# MKE02Z4 register map
Vendor: NXP Semiconductors; Series: Kinetis_E; File version: 1.6
MKE02Z4 NXP Microcontroller
CPU: CM0PLUS r0p0, little endian, no MPU, no FPU, VTOR, 2 interrupt priority bits
Registers are 32-bit, read-write, reset 0x0 unless marked. A register's access mark holds for its fields unless they carry their own. Offsets are from the block's base; lines under a group give offsets from that group; [hi:lo] are bit positions; {n}, {i} and the like mark numbered series; 'fields as' and 'values as' point back to an identical list; <NAME> marks a mode.

## Memory map
0x40020000 FTMRH size 0xD — Flash Memory
0x40031000 IRQ size 0x1 — Interrupt
0x40032000 CRC size 0xC — Cyclic Redundancy Check
0x40037000 PIT size 0x120 — Periodic Interrupt Timer
0x40038000 FTM0 size 0x9C — FlexTimer Module
0x40039000 FTM1 size 0x9C — FlexTimer Module
0x4003A000 FTM2 size 0x9C — FlexTimer Module
0x4003B000 ADC size 0x1C — Analog-to-digital converter
0x4003D000 RTC size 0xC — Real-time counter
0x40048000 SIM size 0x1C — System Integration Module
0x40049000 PORT size 0x10 — Port control and interrupts
0x40052000 WDOG size 0x8 — Watchdog timer
0x40064000 ICS size 0x5 — Clock management
0x40065000 OSC size 0x1 — Oscillator
0x40066000 I2C0 size 0xC — Inter-Integrated Circuit
0x4006A000 UART0 size 0x8 — Universal Asynchronous Receiver/Transmitter (UART)
0x4006B000 UART1 size 0x8 — Universal Asynchronous Receiver/Transmitter (UART)
0x4006C000 UART2 size 0x8 — Universal Asynchronous Receiver/Transmitter (UART)
0x40073000 ACMP0 size 0x4 — Analog comparator
0x40074000 ACMP1 size 0x4 — Analog comparator
0x40076000 SPI0 size 0x8 — Serial Peripheral Interface
0x40077000 SPI1 size 0x8 — Serial Peripheral Interface
0x40079000 KBI0 size 0x3 — Keyboard interrupts
0x4007A000 KBI1 size 0x3 — Keyboard interrupts
0x4007D000 PMC size 0x2 — Power management
0x400FF000 GPIOA size 0x1C — General Purpose Input/Output
0x400FF040 GPIOB size 0x1C — General Purpose Input/Output
0xF0002000 ROM size 0x1000 — System ROM
0xF0003000 MCM blocks up to offset 0x10 — Core Platform Miscellaneous Control Module
0xF8000000 FGPIOA size 0x1C — General Purpose Input/Output
0xF8000040 FGPIOB size 0x1C — General Purpose Input/Output

## Interrupts
5 FTMRH
6 PMC
7 IRQ (GPIOA)
8 I2C0
10 SPI0
11 SPI1
12 UART0
13 UART1
14 UART2
15 ADC
16 ACMP0
17 FTM0
18 FTM1
19 FTM2
20 RTC
21 ACMP1
22 PIT_CH0 (PIT)
23 PIT_CH1 (PIT)
24 KBI0
25 KBI1
27 ICS
28 WDOG

## IRQ — Interrupt
Base 0x40031000; register names take the prefix IRQ_
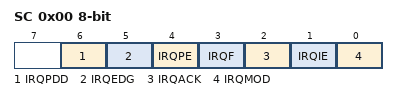
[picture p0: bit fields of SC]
0x00 SC 8-bit — Interrupt Pin Request Status and Control Register
  [6] IRQPDD — Interrupt Request (IRQ) Pull Device Disable
    0=IRQ pull device enabled if IRQPE = 1; 1=IRQ pull device disabled if IRQPE = 1
  [5] IRQEDG — Interrupt Request (IRQ) Edge Select
    0=IRQ is falling-edge or falling-edge/low-level sensitive; 1=IRQ is rising-edge or rising-edge/high-level sensitive
  [4] IRQPE — IRQ Pin Enable
    0=IRQ pin function is disabled; 1=IRQ pin function is enabled
  [3] IRQF ro — IRQ Flag
    0=No IRQ request; 1=IRQ event is detected
  [2] IRQACK wo — IRQ Acknowledge
  [1] IRQIE — IRQ Interrupt Enable
    0=Interrupt request when IRQF set is disabled (use polling); 1=Interrupt requested whenever IRQF = 1
  [0] IRQMOD — IRQ Detection Mode
    0=IRQ event is detected only on falling/rising edges; 1=IRQ event is detected on falling/rising edges and low/high levels

## CRC — Cyclic Redundancy Check
Base 0x40032000; register names take the prefix CRC_
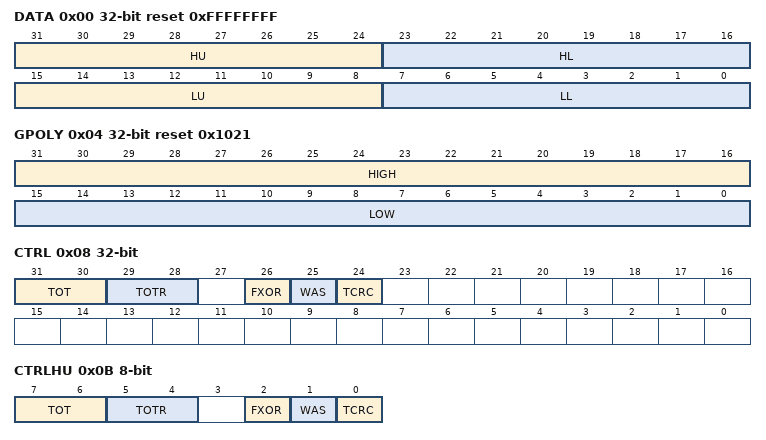
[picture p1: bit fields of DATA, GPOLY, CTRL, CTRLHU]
0x00 DATA reset 0xFFFFFFFF (CRC view) — CRC Data register
  [31:24] HU — CRC High Upper Byte
  [23:16] HL — CRC High Lower Byte
  [15:8] LU — CRC Low Upper Byte
  [7:0] LL — CRC Low Lower Byte
0x00 DATAL 16-bit reset 0xFFFF (CRC view) — CRC_DATAL register.
  [15:0] DATAL — DATAL stores the lower 16 bits of the 16/32 bit CRC
0x00 DATALL 8-bit reset 0xFF (CRC view) — CRC_DATALL register.
  [7:0] DATALL — CRCLL stores the first 8 bits of the 32 bit DATA
0x01 DATALU 8-bit reset 0xFF — CRC_DATALU register.
  [7:0] DATALU — DATALL stores the second 8 bits of the 32 bit CRC
0x02 DATAH 16-bit reset 0xFFFF (CRC view) — CRC_DATAH register.
  [15:0] DATAH — DATAH stores the high 16 bits of the 16/32 bit CRC
0x02 DATAHL 8-bit reset 0xFF (CRC view) — CRC_DATAHL register.
  [7:0] DATAHL — DATAHL stores the third 8 bits of the 32 bit CRC
0x03 DATAHU 8-bit reset 0xFF — CRC_DATAHU register.
  [7:0] DATAHU — DATAHU stores the fourth 8 bits of the 32 bit CRC
0x04 GPOLY reset 0x1021 (CRC view) — CRC Polynomial register
  [31:16] HIGH — High Polynominal Half-word
  [15:0] LOW — Low Polynominal Half-word
0x04 GPOLYL 16-bit reset 0xFFFF (CRC view) — CRC_GPOLYL register.
  [15:0] GPOLYL — POLYL stores the lower 16 bits of the 16/32 bit CRC polynomial value
0x04 GPOLYLL 8-bit reset 0xFF (CRC view) — CRC_GPOLYLL register.
  [7:0] GPOLYLL — POLYLL stores the first 8 bits of the 32 bit CRC
0x05 GPOLYLU 8-bit reset 0xFF — CRC_GPOLYLU register.
  [7:0] GPOLYLU — POLYLL stores the second 8 bits of the 32 bit CRC
0x06 GPOLYH 16-bit reset 0xFFFF (CRC view) — CRC_GPOLYH register.
  [15:0] GPOLYH — POLYH stores the high 16 bits of the 16/32 bit CRC polynomial value
0x06 GPOLYHL 8-bit reset 0xFF (CRC view) — CRC_GPOLYHL register.
  [7:0] GPOLYHL — POLYHL stores the third 8 bits of the 32 bit CRC
0x07 GPOLYHU 8-bit reset 0xFF — CRC_GPOLYHU register.
  [7:0] GPOLYHU — POLYHU stores the fourth 8 bits of the 32 bit CRC
0x08 CTRL — CRC Control register
  [31:30] TOT — Type Of Transpose For Writes
    0=No transposition; 1=Bits in bytes are transposed; bytes are not transposed; 2=Both bits in bytes and bytes are transposed; 3=Only bytes are transposed; no bits in a byte are transposed
  [29:28] TOTR — Type Of Transpose For Read
    values as TOT
  [26] FXOR — Complement Read Of CRC Data Register
    0=No XOR on reading; 1=Invert or complement the read value of the CRC Data register
  [25] WAS — Write CRC Data Register As Seed
    0=Writes to the CRC data register are data values; 1=Writes to the CRC data register are seed values
  [24] TCRC — Width of CRC protocol.
    0=16-bit CRC protocol; 1=32-bit CRC protocol
0x0B CTRLHU 8-bit — CRC_CTRLHU register.
  [7:6] TOT
    0=No Transposition; 1=Bits in bytes are transposed, bytes are not transposed; 2=Both bits in bytes and bytes are transposed; 3=Only bytes are transposed; no bits in a byte are transposed
  [5:4] TOTR
    values as TOT
  [2] FXOR
    0=No XOR on reading; 1=Invert or complement the read value of CRC data register
  [1] WAS
    0=Writes to CRC data register are data values; 1=Writes to CRC data reguster are seed values
  [0] TCRC
    0=16-bit CRC protocol; 1=32-bit CRC protocol

## Licence text in the file
Copyright 2016-2018 NXP SPDX-License-Identifier: BSD-3-Clause
